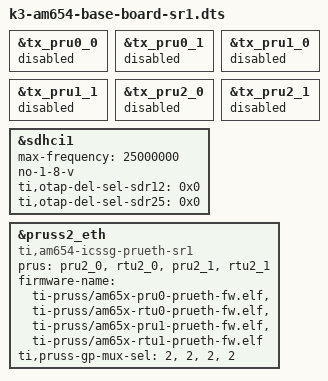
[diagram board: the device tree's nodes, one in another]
// SPDX-License-Identifier: GPL-2.0
/*
 * Copyright (C) 2020 Texas Instruments Incorporated - http://www.ti.com/
 */
#include "k3-am654-base-board.dts"
#include "k3-am654-base-board-u-boot.dtsi"

&tx_pru0_0 {
	status = "disabled";
};

&tx_pru0_1 {
	status = "disabled";
};

&tx_pru1_0 {
	status = "disabled";
};

&tx_pru1_1 {
	status = "disabled";
};

&tx_pru2_0 {
	status = "disabled";
};

&tx_pru2_1 {
	status = "disabled";
};

&sdhci1{
	max-frequency = <25000000>;
	no-1-8-v;
	ti,otap-del-sel-sdr12 = <0x0>;
	ti,otap-del-sel-sdr25 = <0x0>;
};

&pruss2_eth {
	compatible = "ti,am654-icssg-prueth-sr1";
	prus = <&pru2_0>, <&rtu2_0>, <&pru2_1>, <&rtu2_1>;
	firmware-name = "ti-pruss/am65x-pru0-prueth-fw.elf",
			"ti-pruss/am65x-rtu0-prueth-fw.elf",
			"ti-pruss/am65x-pru1-prueth-fw.elf",
			"ti-pruss/am65x-rtu1-prueth-fw.elf";
	ti,pruss-gp-mux-sel = <2>,      /* MII mode */
			      <2>,
			      <2>,      /* MII mode */
			      <2>;
};
